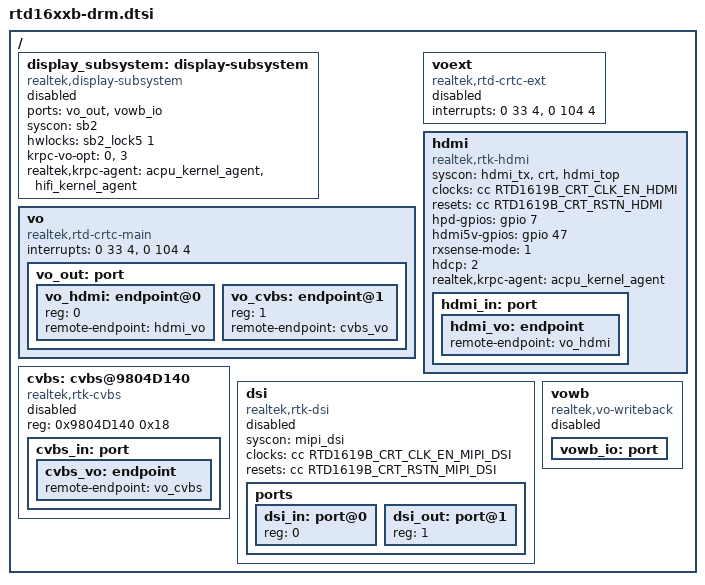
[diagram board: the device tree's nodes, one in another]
/* PLEASE include this file inside a node */
/ {
	display_subsystem: display-subsystem {
		compatible = "realtek,display-subsystem";
		ports = <&vo_out>, <&vowb_io>;
		syscon = <&sb2>;
		hwlocks = <&sb2_lock5 1>;
		krpc-vo-opt = <0>, <3>;
		realtek,krpc-agent = <&acpu_kernel_agent>, <&hifi_kernel_agent>;
		status = "disabled";
	};

	vo: vo {
		compatible = "realtek,rtd-crtc-main";
		interrupts = <0 33 4>, <0 104 4>;
		vo_out: port {
			#address-cells = <1>;
			#size-cells = <0>;
			vo_hdmi: endpoint@0 {
				reg = <0>;
				remote-endpoint = <&hdmi_vo>;
			};
			vo_cvbs: endpoint@1 {
				reg = <1>;
				remote-endpoint = <&cvbs_vo>;
			};
		};
	};

	voext: voext {
		compatible = "realtek,rtd-crtc-ext";
		interrupts = <0 33 4>, <0 104 4>;
		status = "disabled";
	};

	hdmi: hdmi {
		compatible = "realtek,rtk-hdmi";
		syscon = <&hdmi_tx>, <&crt>, <&hdmi_top>;
		clocks = <&cc RTD1619B_CRT_CLK_EN_HDMI>;
		clock-names = "clk_en_hdmi";
		resets = <&cc RTD1619B_CRT_RSTN_HDMI>;
		reset-names = "rstn_hdmi";
		hpd-gpios = <&gpio 7 GPIO_PULL_DOWN>;
		hdmi5v-gpios = <&gpio 47 GPIO_ACTIVE_HIGH>;
		rxsense-mode = <1>;
		hdcp = <2>;
		realtek,krpc-agent = <&acpu_kernel_agent>;
		hdmi_in: port {
			hdmi_vo: endpoint {
				remote-endpoint = <&vo_hdmi>;
			};
		};
	};

	cvbs: cvbs@9804D140 {
		compatible = "realtek,rtk-cvbs";
		reg = <0x9804D140 0x18>;
		status = "disabled";
		cvbs_in: port {
			cvbs_vo: endpoint {
				remote-endpoint = <&vo_cvbs>;
			};
		};
	};

	dsi: dsi {
		compatible = "realtek,rtk-dsi";
		syscon = <&mipi_dsi>;
		clocks = <&cc RTD1619B_CRT_CLK_EN_MIPI_DSI>;
		clock-names = "clk_en_dsi";
		resets = <&cc RTD1619B_CRT_RSTN_MIPI_DSI>;
		reset-names = "dsi";
		status = "disabled";
		ports {
			#address-cells = <1>;
			#size-cells = <0>;
			dsi_in: port@0 {
				reg = <0>;
			};
			dsi_out: port@1 {
				reg = <1>;
			};
		};
	};

	vowb: vowb {
		compatible = "realtek,vo-writeback";
		status = "disabled";
		vowb_io: port {
		};
	};
};
